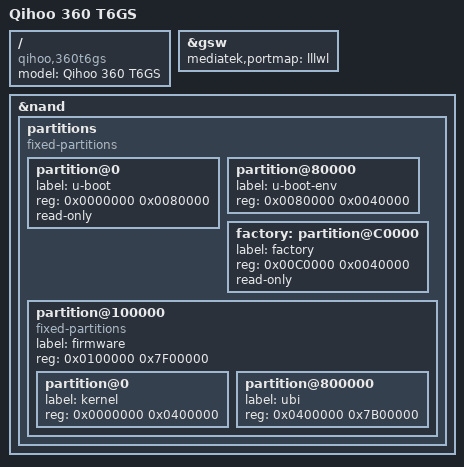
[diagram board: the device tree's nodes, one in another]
// SPDX-License-Identifier: GPL-2.0-or-later OR MIT

#include "mt7621_qihoo_360t6gs.dtsi"

/ {
	compatible = "qihoo,360t6gs", "mediatek,mt7621-soc";
	model = "Qihoo 360 T6GS";
};

&gsw {
	mediatek,portmap = "lllwl";
	status = "okay";
};

&nand {
	status = "okay";

	partitions {
		compatible = "fixed-partitions";
		#address-cells = <1>;
		#size-cells = <1>;

		partition@0 {
			label = "u-boot";
			reg = <0x0000000 0x0080000>;
			read-only;
		};

		partition@80000 {
			label = "u-boot-env";
			reg = <0x0080000 0x0040000>;
		};

		factory: partition@C0000 {
			label = "factory";
			reg = <0x00C0000 0x0040000>;
			read-only;
		};

		/* The original firmware contains MTD2 Factory and MTD5 factory (case sensitive).
		 * MTD2 only stores EEPROM calibration, while MTD5 stores MAC/SN information.
		 * You need to merge these two partitions before flashing the firmware,
		 * otherwise information will be lost.
		 */

		partition@100000 {
			label = "firmware";
			reg = <0x0100000 0x7F00000>;

			compatible = "fixed-partitions";
			#address-cells = <1>;
			#size-cells = <1>;

			partition@0 {
				label = "kernel";
				reg = <0x0000000 0x0400000>;
			};

			partition@800000 {
				label = "ubi";
				reg = <0x0400000 0x7B00000>;
			};
		};
	};
};
